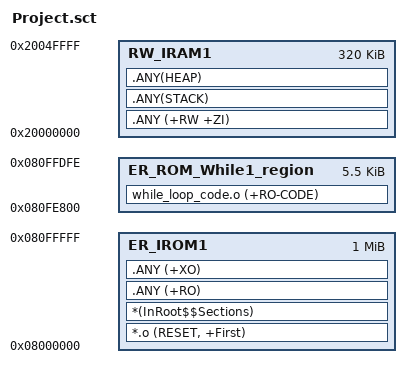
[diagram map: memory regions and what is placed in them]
; *************************************************************
; *** Scatter-Loading Description File generated by uVision ***
; *************************************************************

LR_IROM1 0x08000000 0x00100000  {    ; load region size_region
  ER_IROM1 0x08000000 0x00100000  {  ; load address = execution address
   *.o (RESET, +First)
   *(InRoot$$Sections)
   .ANY (+RO)
   .ANY (+XO)
  }
  RW_IRAM1 0x20000000  0x50000 {  ; RW data
   .ANY (+RW +ZI)
  .ANY(STACK)
  .ANY(HEAP)   
  }
}

;LR_ROM_While1_region 0x080FE800 0x15FF  {
;ER_ROM_While1_region 0x080FE800 0x15FF  {
;   *.o (.ROM_While1_section)
;  }
;  }

LR_ROM_While1_region 0x080FE800 0x15FF {
  ER_ROM_While1_region 0x080FE800 0x15FF  {  ; load address = execution address
    while_loop_code.o (+RO-CODE)
	}
  }  
